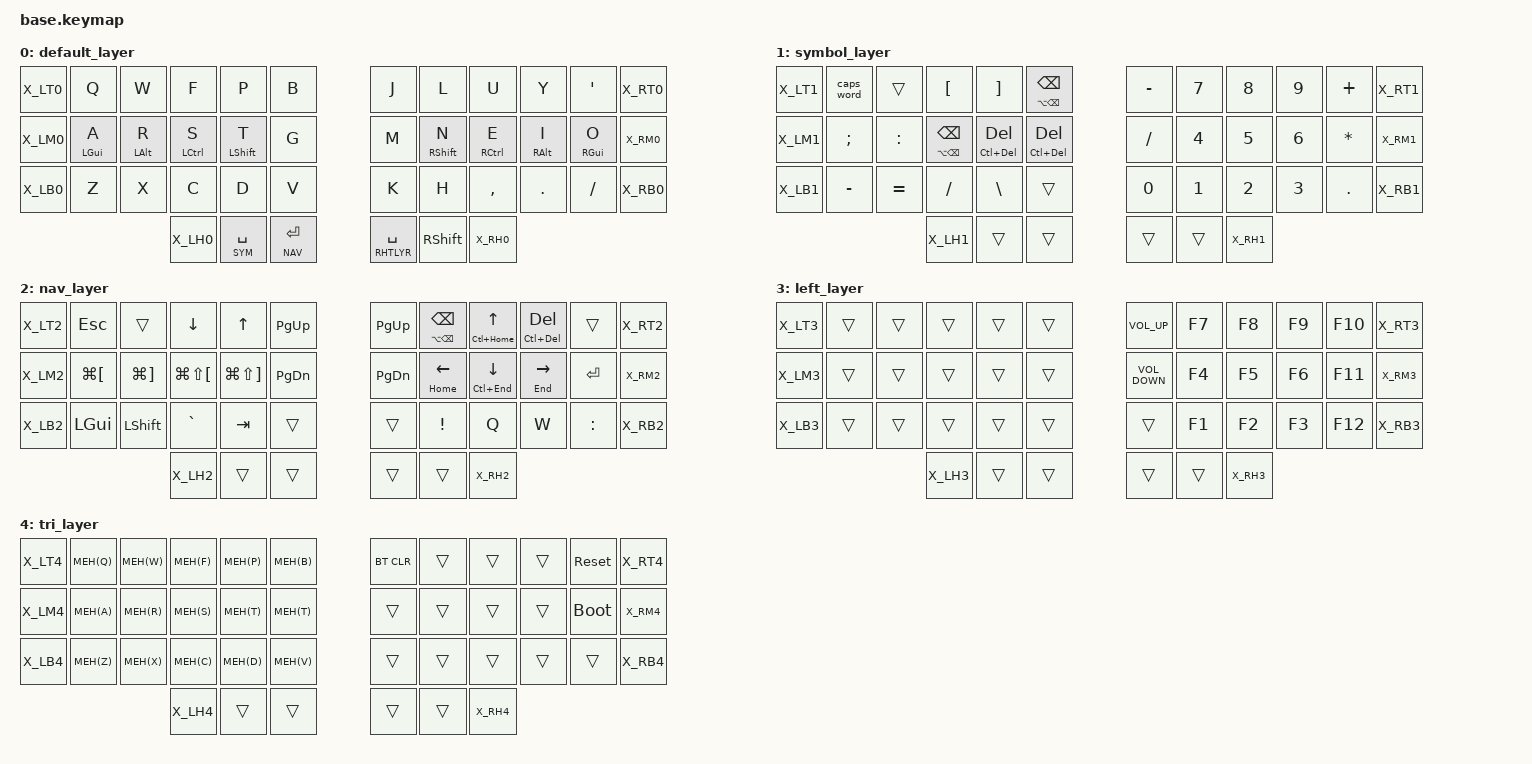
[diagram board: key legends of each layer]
#include <behaviors.dtsi>
#include <dt-bindings/zmk/keys.h>
#include <dt-bindings/zmk/outputs.h>
#include <dt-bindings/zmk/bt.h>
#include "helper.h"
#include "extra_keys.h"

#define DEF 0
#define SYM 1
#define NAV 2
#define RHTLYR 3
#define TRI 4

#define XXX &none
#define ___ &trans

#define QUICK_TAP_MS 175

&sk {  // sticky-key config
    release-after-ms = <600>;  // release after 0.6s
    quick-release;             // no double capitalization when rolling keys
};

&mt { 
    flavor = "tap-preferred";
    tapping-term-ms = <220>;
    quick-tap-ms = <220>;
    hold-trigger-key-positions = <0>;
};

&lt {  // layer-tap config
    flavor = "balanced";
    tapping-term-ms = <200>;
    quick-tap-ms = <QUICK_TAP_MS>;
};

&soft_off {
    hold-time-ms = <1000>; // Only turn off the keyboard if the key is held for 1 seconds or longer.
};

#define NAV_LEFT  &mt HOME LEFT      // tap: left  | long-tap: beginning of line
#define NAV_RIGHT &mt END RIGHT      // tap: right | long-tap: end       of line
#define NAV_UP    &mt LC(HOME) UP    // tap: up    | long-tap: beginning of document
#define NAV_DOWN  &mt LC(END) DOWN   // tap: down  | long-tap: end       of document
#define NAV_BSPC  &mt LA(BSPC) BSPC  // tap: bspc  | long-tap: delete word backward
#define NAV_DEL   &mt LC(DEL) DEL    // tap: del   | long-tap: delete word forward
#define FWD &kp LG(RBKT)
#define BACK &kp LG(LBKT)
#define TAB_L &kp LG(LS(LBKT))
#define TAB_R &kp LG(LS(RBKT))
#define SPACE_L &kp LG(LA(LEFT))
#define SPACE_R &kp LG(LA(RIGHT))
#define SW_WIN &kp UP
#define SW_APP &kp UP
#define MEH(key) &kp LS(LC(LA(key)))
#define VOL_UP &kp C_VOLUME_UP
#define VOL_DN &kp C_VOLUME_DOWN


#define KEYS_L LT0 LT1 LT2 LT3 LT4 LM0 LM1 LM2 LM3 LM4 LB0 LB1 LB2 LB3 LB4  // left hand
#define KEYS_R RT0 RT1 RT2 RT3 RT4 RM0 RM1 RM2 RM3 RM4 RB0 RB1 RB2 RB3 RB4  // right hand
#define THUMBS LH1 LH0 RH0 RH1                                       // thumbs

// urob's aswesome home mod feature (https://github.com/urob/zmk-config/)
ZMK_BEHAVIOR(hml, hold_tap,
    flavor = "balanced";
    tapping-term-ms = <280>;
    quick-tap-ms = <175>;                // repeat on tap-into-hold
    require-prior-idle-ms = <150>;
    bindings = <&kp>, <&kp>;
    hold-trigger-key-positions = <KEYS_R THUMBS>;
    hold-trigger-on-release;             // delay positional check until key-release
)

ZMK_BEHAVIOR(hmr, hold_tap,
    flavor = "balanced";
    tapping-term-ms = <280>;
    quick-tap-ms = <175>;                // repeat on tap-into-hold
    require-prior-idle-ms = <150>;
    bindings = <&kp>, <&kp>;
    hold-trigger-key-positions = <KEYS_L THUMBS>;
    hold-trigger-on-release;             // delay positional check until key-release
)

#define MAKE_HRM(NAME, HOLD, TAP, TRIGGER_POS) \
    ZMK_BEHAVIOR(NAME, hold_tap, \
        flavor = "balanced"; \
        tapping-term-ms = <280>; \
        quick-tap-ms = <QUICK_TAP_MS>; \
        require-prior-idle-ms = <150>; \
        bindings = <HOLD>, <TAP>; \
        hold-trigger-key-positions = <TRIGGER_POS>; \
        hold-trigger-on-release; \
    )
MAKE_HRM(hml, &kp, &kp, KEYS_R THUMBS)  // left-hand HRMs
MAKE_HRM(hmr, &kp, &kp, KEYS_L THUMBS)  // right-hand HRMs

MAKE_HRM(hml_repeat, &kp, &key_repeat, KEYS_R THUMBS)  // used for HRM-combo
MAKE_HRM(hmr_lpar_lt, &kp, &lpar_lt, KEYS_L THUMBS)    // "    "   "   "
MAKE_HRM(hmr_rpar_gt, &kp, &rpar_gt, KEYS_L THUMBS)    // "    "   "   "c


// reuse basic mod-morph scheme
#define SIMPLE_MORPH(NAME, MOD, BINDING1, BINDING2) \
    ZMK_BEHAVIOR(NAME, mod_morph, \
        mods = <(MOD_L ## MOD|MOD_R ## MOD)>; \
        bindings = <BINDING1>, <BINDING2>; \
    )
// tap: left/right parenthesis | shft + tap: less-than/greater-than
SIMPLE_MORPH(lpar_lt, SFT, &kp LPAR, &kp LT)
SIMPLE_MORPH(rpar_gt, SFT, &kp RPAR, &kp GT)


/ {
    combos {
        compatible = "zmk,combos";

        #include "combos.dtsi"
    };

    behaviors {
        ht: hold_tap {
            compatible = "zmk,behavior-hold-tap";
            #binding-cells = <2>;
            flavor = "tap-preferred";
            tapping-term-ms = <220>;
            quick-tap-ms = <150>;
            require-prior-idle-ms = <100>;
            bindings = <&kp>, <&kp>;
        };
    };

    conditional_layers {
        compatible = "zmk,conditional-layers";
        tri_layer {
            if-layers = <NAV SYM>;
            then-layer = <TRI>;
        };
    };

    keymap {
        compatible = "zmk,keymap";
        default_layer {
            bindings = <
        //╭───────╮ ╭──────────────┬──────────────┬──────────────┬────────────────┬──────────────╮   ╭───────────────┬──────────────┬──────────────┬──────────────┬──────────────╮ ╭───────╮
            X_LT0     &kp Q         &kp W          &kp F           &kp P            &kp B              &kp J           &kp L          &kp U          &kp Y           &kp SQT         X_RT0
        //├───────┤ ├──────────────┼──────────────┼──────────────┼────────────────┼──────────────┤   ├───────────────┼──────────────┼──────────────┼──────────────┼──────────────┤ ├───────┤
            X_LM0     &hml LGUI A   &hml LALT R     &hml LCTRL S   &hml LSHFT T     &kp G              &kp M           &hmr RSHFT N   &hmr RCTRL E   &hmr RALT I    &hmr RGUI O      X_RM0
        //├───────┤ ├──────────────┼──────────────┼──────────────┼────────────────┼──────────────┤   ├───────────────┼──────────────┼──────────────┼──────────────┼──────────────┤ ├───────┤
            X_LB0     &kp Z         &kp X          &kp C           &kp D            &kp V              &kp K           &kp H          &kp COMMA      &kp DOT        &kp FSLH         X_RB0
        //├───────┤ ╰──────────────┴──────────────┴──────────────┼────────────────┼──────────────┤   ├───────────────┼──────────────┼──────────────┴──────────────┴──────────────╯ ├───────┤
            X_LH0                                                  &lt SYM SPACE    &lt NAV ENTER      &lt RHTLYR SPACE   &kp RSHFT                                                  X_RH0
        //╰───────╯                                              ╰────────────────┴──────────────╯   ╰───────────────┴──────────────╯                                              ╰───────╯
            >;
        };

        symbol_layer {
            bindings = <
        //╭───────╮ ╭──────────┬──────────┬──────────┬──────────┬──────────╮   ╭──────────┬──────────┬──────────┬──────────┬───────────╮ ╭───────╮
            X_LT1    &caps_word  &trans     &kp LBKT   &kp RBKT   NAV_BSPC       &kp MINUS  &kp N7     &kp N8     &kp N9     &kp PLUS      X_RT1
        //├───────┤ ├──────────┼──────────┼──────────┼──────────┼──────────┤   ├──────────┼──────────┼──────────┼──────────┼───────────┤ ├───────┤
            X_LM1     &kp SEMI  &kp COLON   NAV_BSPC   NAV_DEL    NAV_DEL        &kp FSLH   &kp N4     &kp N5     &kp N6     &kp ASTRK     X_RM1
        //├───────┤ ├──────────┼──────────┼──────────┼──────────┼──────────┤   ├──────────┼──────────┼──────────┼──────────┼───────────┤ ├───────┤
            X_LB1     &kp MINUS  &kp EQUAL  &kp FSLH   &kp BSLH   &trans         &kp N0     &kp N1     &kp N2     &kp N3     &kp DOT       X_RB1
        //├───────┤ ╰──────────┴──────────┴──────────┼──────────┼──────────┤   ├──────────┼──────────┼──────────┴──────────┴───────────╯ ├───────┤
            X_LH1                                      &trans     &trans         &trans     &trans                                         X_RH1
        //╰───────╯                                  ╰──────────┴──────────╯   ╰──────────┴──────────╯                                   ╰───────╯
            >;
        };

        nav_layer {
            // display-name = "NAV";
            bindings = <
        //╭───────╮ ╭───────────┬───────────┬──────────┬──────────┬──────────╮   ╭─────────────┬──────────────┬─────────────┬─────────────┬─────────────╮ ╭───────╮
            X_LT2     &kp ESC     &trans      &kp DOWN   &kp UP     &kp PG_UP      &kp PG_UP     NAV_BSPC       NAV_UP        NAV_DEL       &trans          X_RT2
        //├───────┤ ├───────────┼───────────┼──────────┼──────────┼──────────┤   ├─────────────┼──────────────┼─────────────┼─────────────┼─────────────┤ ├───────┤
            X_LM2     BACK        FWD         TAB_L      TAB_R      &kp PG_DN      &kp PG_DN     NAV_LEFT       NAV_DOWN      NAV_RIGHT     &kp RET         X_RM2
        //├───────┤ ├───────────┼───────────┼──────────┼──────────┼──────────┤   ├─────────────┼──────────────┼─────────────┼─────────────┼─────────────┤ ├───────┤
            X_LB2     &kp LGUI    &kp LSHFT   &kp GRAVE  &kp TAB    &trans         &trans        &kp EXCL       &kp Q         &kp W         &kp COLON       X_RB2
        //├───────┤ ╰───────────┴───────────┴──────────┼──────────┼──────────┤   ├─────────────┼──────────────┼─────────────┴─────────────┴─────────────╯ ├───────┤
            X_LH2                                        &trans     &trans         &trans        &trans                                                     X_RH2
        //╰───────╯                                    ╰──────────┴──────────╯   ╰─────────────┴──────────────╯                                           ╰───────╯
            >;
        };

        left_layer {
            bindings = <
        //╭───────╮ ╭──────────┬──────────┬──────────┬──────────┬──────────╮   ╭──────────┬──────────┬──────────┬──────────┬──────────╮ ╭───────╮
        //        │            │          │          │          │          │   │ Vol Up   │ F7       │ F8       │ F9       │ F10      │
            X_LT3     &trans     &trans     &trans     &trans     &trans         VOL_UP     &kp F7     &kp F8     &kp F9     &kp F10      X_RT3
        //├───────┤ ├──────────┼──────────┼──────────┼──────────┼──────────┤   ├──────────┼──────────┼──────────┼──────────┼──────────┤ ├───────┤
        //                     │          │          │          │          │   │ Vol Down │ F4       │ F5       │ F6       │ F11      │
            X_LM3     &trans     &trans     &trans     &trans     &trans         VOL_DN     &kp F4     &kp F5     &kp F6     &kp F11      X_RM3
        //├───────┤ ├──────────┼──────────┼──────────┼──────────┼──────────┤   ├──────────┼──────────┼──────────┼──────────┼──────────┤ ├───────┤
        //          │          │          │          │          │          │   │          │ F1       │ F2       │ F3       │ F12      │
            X_LB3     &trans     &trans     &trans     &trans     &trans         &trans     &kp F1     &kp F2     &kp F3     &kp F12      X_RB3
        //├───────┤ ╰──────────┴──────────┴──────────┼──────────┼──────────┤   ├──────────┼──────────┼──────────┴──────────┴──────────╯ ├───────┤
            X_LH3                                      &trans     &trans         &trans     &trans                                        X_RH3
        //╰───────╯                                  ╰──────────┴──────────╯   ╰──────────┴──────────╯                                  ╰───────╯
            >;
        };

        tri_layer {
            bindings = <
        //╭───────╮ ╭──────────┬──────────┬──────────┬──────────┬──────────╮   ╭──────────┬──────────┬──────────┬──────────┬──────────╮ ╭───────╮
            X_LT4     MEH(Q)     MEH(W)     MEH(F)     MEH(P)     MEH(B)         &bt BT_CLR &trans     &trans     &trans    &sys_reset    X_RT4
        //├───────┤ ├──────────┼──────────┼──────────┼──────────┼──────────┤   ├──────────┼──────────┼──────────┼──────────┼──────────┤ ├───────┤
            X_LM4     MEH(A)     MEH(R)     MEH(S)     MEH(T)     MEH(T)         &trans     &trans     &trans     &trans    &bootloader   X_RM4
        //├───────┤ ├──────────┼──────────┼──────────┼──────────┼──────────┤   ├──────────┼──────────┼──────────┼──────────┼──────────┤ ├───────┤
            X_LB4     MEH(Z)     MEH(X)     MEH(C)     MEH(D)     MEH(V)         &trans     &trans     &trans     &trans     &trans       X_RB4
        //├───────┤ ╰──────────┴──────────┴──────────┼──────────┼──────────┤   ├──────────┼──────────┼──────────┴──────────┴──────────╯ ├───────┤
            X_LH4                                      &trans     &trans         &trans     &trans                                        X_RH4
        //╰───────╯                                  ╰──────────┴──────────╯   ╰──────────┴──────────╯                                  ╰───────╯
            >;
        };
    };
};
